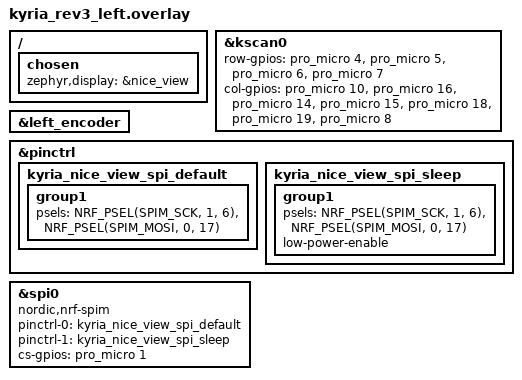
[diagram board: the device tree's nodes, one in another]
/*
 * Copyright (c) 2023 The ZMK Contributors
 *
 * SPDX-License-Identifier: MIT
 */

#include "kyria_rev3.dtsi"

&kscan0 {
    row-gpios
    = <&pro_micro 4 (GPIO_ACTIVE_HIGH | GPIO_PULL_DOWN)>
    , <&pro_micro 5 (GPIO_ACTIVE_HIGH | GPIO_PULL_DOWN)>
    , <&pro_micro 6 (GPIO_ACTIVE_HIGH | GPIO_PULL_DOWN)>
    , <&pro_micro 7 (GPIO_ACTIVE_HIGH | GPIO_PULL_DOWN)>
    ;
    col-gpios
    = <&pro_micro 10 GPIO_ACTIVE_HIGH>
    , <&pro_micro 16 GPIO_ACTIVE_HIGH>
    , <&pro_micro 14 GPIO_ACTIVE_HIGH>
    , <&pro_micro 15 GPIO_ACTIVE_HIGH>
    , <&pro_micro 18 GPIO_ACTIVE_HIGH>
    , <&pro_micro 19 GPIO_ACTIVE_HIGH>
    , <&pro_micro 8 GPIO_ACTIVE_HIGH>
    ;
};

&left_encoder {
    status = "okay";
};
/* ── nice!view (left half) ───────────────────────────────────────────────
 * Wiring (nice!nano v2):
 *   nice!view VCC -> OLED socket VCC
 *   nice!view GND -> OLED socket GND
 *   nice!view CS  -> D1  (P0.06)
 *   nice!view MOSI-> D2  (P0.17)
 *   nice!view SCL -> D9  (P1.06)   NOTE: not the adapter-shield default D3!
 * D3/P0.20 is used by the Kyria matrix (col6 here, row4 on the right half),
 * so the stock nice_view_adapter shield cannot be used; pins set by hand.
 */
&pinctrl {
    kyria_nice_view_spi_default: kyria_nice_view_spi_default {
        group1 {
            psels = <NRF_PSEL(SPIM_SCK, 1, 6)>,
                    <NRF_PSEL(SPIM_MOSI, 0, 17)>;
        };
    };
    kyria_nice_view_spi_sleep: kyria_nice_view_spi_sleep {
        group1 {
            psels = <NRF_PSEL(SPIM_SCK, 1, 6)>,
                    <NRF_PSEL(SPIM_MOSI, 0, 17)>;
            low-power-enable;
        };
    };
};

nice_view_spi: &spi0 {
    compatible = "nordic,nrf-spim";
    status = "okay";
    pinctrl-0 = <&kyria_nice_view_spi_default>;
    pinctrl-1 = <&kyria_nice_view_spi_sleep>;
    pinctrl-names = "default", "sleep";
    cs-gpios = <&pro_micro 1 GPIO_ACTIVE_HIGH>;
};

/* The kyria board overlay (kyria/boards/nice_nano_nrf52840_zmk.overlay)
 * re-points chosen zephyr,display at the (now disabled) SSD1306. Re-assert
 * nice!view here: user config overlays load after all shield overlays.
 */
/ {
    chosen {
        zephyr,display = &nice_view;
    };
};
